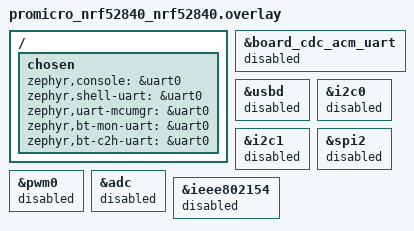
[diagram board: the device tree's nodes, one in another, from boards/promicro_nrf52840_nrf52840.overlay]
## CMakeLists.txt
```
cmake_minimum_required(VERSION 3.20)
find_package(Zephyr REQUIRED HINTS $ENV{ZEPHYR_BASE})
project(helix_nrf52840_mocap_bridge)

get_filename_component(HELIX_ROOT "${CMAKE_CURRENT_LIST_DIR}/../.." ABSOLUTE)

target_sources(app PRIVATE
  src/usbd_init.c
  src/main.cpp
  src/ota_hub_relay.cpp
  ${HELIX_ROOT}/firmware/common/ota/BleOtaService.cpp
)

# OTA flash backend and manager only needed for Tags (node role with MCUboot)
if(CONFIG_HELIX_MOCAP_BRIDGE_ROLE_NODE)
  target_sources(app PRIVATE
    src/ZephyrOtaFlashBackend.cpp
    ${HELIX_ROOT}/firmware/common/ota/OtaManager.cpp
  )
endif()

target_include_directories(app PRIVATE
  src
  ${HELIX_ROOT}/firmware/common/ota
)
```

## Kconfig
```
mainmenu "Helix nRF52840 Mocap Bridge"

source "Kconfig.zephyr"

menu "Helix Mocap Bridge"

choice HELIX_MOCAP_BRIDGE_ROLE
	prompt "Bridge role"
	default HELIX_MOCAP_BRIDGE_ROLE_CENTRAL

config HELIX_MOCAP_BRIDGE_ROLE_CENTRAL
	bool "Central / PRX"

config HELIX_MOCAP_BRIDGE_ROLE_NODE
	bool "Synthetic node / PTX"

endchoice

config HELIX_MOCAP_NODE_ID
	int "Node ID"
	range 1 255
	default 1

config HELIX_MOCAP_CENTRAL_ID
	int "Central ID"
	range 0 255
	default 0

config HELIX_MOCAP_PIPE
	int "ESB pipe"
	range 0 7
	default 0

config HELIX_MOCAP_RF_CHANNEL
	int "ESB RF channel"
	range 0 100
	default 40

config HELIX_MOCAP_SEND_PERIOD_MS
	int "Node send period in milliseconds"
	range 5 5000
	default 20

config HELIX_MOCAP_SESSION_TAG
	int "Session tag"
	range 0 255
	default 77

config HELIX_MOCAP_MAX_TRACKED_NODES
	int "Maximum tracked nodes at the central"
	range 1 16
	default 10

config HELIX_MOCAP_USB_WAIT_FOR_DTR_MS
	int "How long the central waits for host DTR before continuing"
	range 0 30000
	default 5000

config HELIX_MOCAP_USB_VID
	hex "USB vendor ID"
	range 0x0001 0xFFFF
	default 0x1915

config HELIX_MOCAP_USB_PID
	hex "USB product ID"
	range 0x0001 0xFFFF
	default 0x1040 if HELIX_MOCAP_BRIDGE_ROLE_CENTRAL
	default 0x1041 if HELIX_MOCAP_BRIDGE_ROLE_NODE

config HELIX_MOCAP_NODE_LED_DEBUG
	bool "Encode node RF state in LED cadence"
	default y if HELIX_MOCAP_BRIDGE_ROLE_NODE
	help
	  When enabled on node builds, the LED cadence indicates node state:
	  fast blink means the node is alive but has not yet confirmed TX success,
	  medium blink means TX is succeeding without sync anchors, and slow blink
	  means sync anchors are being received from the central.

config HELIX_OTA_HUB_RELAY
	bool "Enable OTA relay from Hub to Tags over BLE"
	default y if HELIX_MOCAP_BRIDGE_ROLE_CENTRAL && BT
	help
	  When enabled, the Hub can relay OTA firmware updates from the PC
	  to Tags over BLE. The PC sends UartOtaProtocol frames over USB CDC,
	  the Hub forwards them to a Tag's BLE GATT OTA service.

config HELIX_OTA_BOOT_WINDOW_MS
	int "BLE OTA boot window in milliseconds (0 to skip)"
	range 0 300000
	default 30000 if HELIX_MOCAP_BRIDGE_ROLE_NODE
	default 0
	help
	  Duration of the BLE OTA advertising window at boot. If a BLE
	  connection is made during this window, OTA proceeds. If not,
	  the device transitions to ESB mocap mode. Set to 0 to skip
	  the BLE window entirely and boot straight into ESB.

config HELIX_OTA_TARGET_ID
	hex "OTA target identity"
	default 0x52840071

config HELIX_BOOTLOADER_VERSION_MAJOR
	int "Bootloader (MCUboot) major version — manually bumped"
	default 1
	help
	  MCUboot does not publish its own version to the app, so we track
	  it manually here. Bump whenever MCUboot itself is rebuilt.

config HELIX_BOOTLOADER_VERSION_MINOR
	int "Bootloader (MCUboot) minor version"
	default 0

config HELIX_BOOTLOADER_VERSION_REVISION
	int "Bootloader (MCUboot) revision"
	default 0

config HELIX_OTA_REBOOT_DELAY_MS
	int "Reboot delay after OTA commit (ms)"
	default 300

# Stage 4 TDMA (Path X1) Kconfig was removed in v22 after the FIFO=1
# Hub config change (docs/RF_FIFO1_DISCOVERY.md) superseded Stage 4's
# value proposition. See git tag stage4-tdma-path-x1-reference for
# the implementation, docs/archive/rf/RF_STAGE4_EXPLORATORY.md for
# the design rationale, and docs/reviews/*stage4_fate* for the
# delete decision.

endmenu
```

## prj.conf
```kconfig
CONFIG_GPIO=y
CONFIG_SERIAL=y
CONFIG_CONSOLE=y
CONFIG_UART_CONSOLE=y
CONFIG_PRINTK=y
CONFIG_UART_LINE_CTRL=y

CONFIG_LOG=y
CONFIG_LOG_MODE_IMMEDIATE=y
CONFIG_LOG_DEFAULT_LEVEL=3
CONFIG_LOG_BACKEND_UART=y
CONFIG_LOG_PRINTK=y

CONFIG_ESB=y
CONFIG_MAIN_STACK_SIZE=3072
```

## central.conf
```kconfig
CONFIG_HELIX_MOCAP_BRIDGE_ROLE_CENTRAL=y
CONFIG_HELIX_MOCAP_BRIDGE_ROLE_NODE=n

CONFIG_USB_DEVICE_STACK_NEXT=y
CONFIG_CDC_ACM_SERIAL_INITIALIZE_AT_BOOT=n
CONFIG_USBD_CDC_ACM_CLASS=y
CONFIG_USBD_LOG_LEVEL_ERR=y
CONFIG_UDC_DRIVER_LOG_LEVEL_ERR=y
CONFIG_USBD_CDC_ACM_LOG_LEVEL_ERR=y

# C++ support for OTA relay modules
CONFIG_CPP=y
CONFIG_NEWLIB_LIBC=y
CONFIG_STD_CPP17=y

# BLE central for OTA relay to Tags
CONFIG_BT=y
CONFIG_BT_CENTRAL=y
CONFIG_BT_GATT_CLIENT=y
# Auto-exchange ATT MTU on connect. Without this, MTU stays at the spec
# default of 23 bytes and bt_gatt_write() for payloads > 20 B (e.g. our
# 132 B OTA data chunks) falls back to Prepare/Execute Write, which the
# Tag's OTA data characteristic rejects with BT_ATT_ERR_NOT_SUPPORTED (0x06).
CONFIG_BT_GATT_AUTO_UPDATE_MTU=y
CONFIG_BT_DEVICE_NAME="HHub"
CONFIG_BT_DEVICE_NAME_DYNAMIC=y
CONFIG_BT_DEVICE_NAME_MAX=16
CONFIG_BT_MAX_CONN=1
CONFIG_BT_L2CAP_TX_MTU=247
CONFIG_BT_BUF_ACL_TX_SIZE=251
CONFIG_BT_BUF_ACL_RX_SIZE=251
CONFIG_BT_CTLR_DATA_LENGTH_MAX=251
CONFIG_BT_CTLR_PHY_2M=y

# Suppress BLE log spam during relay (prevents TX buffer overflow)
CONFIG_BT_LOG_LEVEL_ERR=y
CONFIG_BT_HCI_CORE_LOG_LEVEL_ERR=y

# ESB+BLE coexistence: same pattern as Tags
CONFIG_ESB_DYNAMIC_INTERRUPTS=y

# Force FIFO depth 1 (experiment 2026-04-23): the default ESB_TX_FIFO_SIZE=8
# lets Hub queue up to 8 anchors deep. Combined with asymmetric FIFO drain
# on slow-path ACK transmission, that drives a ~10ms bias in the Stage 3
# midpoint estimator (see docs/RF_V20_FINDINGS.md). Depth 1 forces only ONE
# in-flight anchor at a time; if Hub misses the TIFS window, the anchor is
# simply not queued (rather than piling up in FIFO). The Stage 2 rx_node_id
# filter should absorb the resulting "empty ACK" cases on Tags.
CONFIG_ESB_TX_FIFO_SIZE=1
CONFIG_MPSL_DYNAMIC_INTERRUPTS=y
CONFIG_BT_UNINIT_MPSL_ON_DISABLE=y
CONFIG_BT_LL_SOFTDEVICE=y

# USB CDC RX for receiving OTA commands from PC
CONFIG_UART_INTERRUPT_DRIVEN=y

# Stack/heap for BLE + ESB + C++ + USB
CONFIG_HEAP_MEM_POOL_SIZE=8192
CONFIG_MAIN_STACK_SIZE=8192
CONFIG_SYSTEM_WORKQUEUE_STACK_SIZE=4096

CONFIG_REBOOT=y
```

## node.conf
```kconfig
CONFIG_HELIX_MOCAP_BRIDGE_ROLE_NODE=y
CONFIG_HELIX_MOCAP_BRIDGE_ROLE_CENTRAL=n

# Stage 4 TDMA was deleted in v22 after FIFO=1 superseded it. The
# CONFIG_HELIX_STAGE4_* Kconfig entries no longer exist; see
# docs/archive/rf/RF_STAGE4_EXPLORATORY.md for the history.

# C++ support for OTA modules
CONFIG_CPP=y
CONFIG_NEWLIB_LIBC=y
CONFIG_STD_CPP17=y

# Flash + MCUboot for OTA
CONFIG_FLASH=y
CONFIG_FLASH_MAP=y
CONFIG_FLASH_PAGE_LAYOUT=y
CONFIG_STREAM_FLASH=y
CONFIG_BOOTLOADER_MCUBOOT=y
CONFIG_IMG_MANAGER=y
CONFIG_MCUBOOT_IMG_MANAGER=y
CONFIG_MCUBOOT_IMGTOOL_SIGN_VERSION="22.0.0+0"
CONFIG_REBOOT=y

# BLE for OTA boot window
CONFIG_BT=y
CONFIG_BT_PERIPHERAL=y
CONFIG_BT_DEVICE_NAME="HTag"
CONFIG_BT_DEVICE_NAME_DYNAMIC=y
CONFIG_BT_DEVICE_NAME_MAX=16
CONFIG_BT_DEVICE_APPEARANCE=0
CONFIG_BT_MAX_CONN=1
CONFIG_BT_MAX_PAIRED=1
CONFIG_BT_GATT_DYNAMIC_DB=n
CONFIG_BT_L2CAP_TX_MTU=247
CONFIG_BT_BUF_ACL_TX_SIZE=251
CONFIG_BT_BUF_ACL_RX_SIZE=251
CONFIG_BT_CTLR_DATA_LENGTH_MAX=251
CONFIG_BT_CTLR_PHY_2M=y
# Extra ACL RX headroom for OTA data bursts from the Hub
CONFIG_BT_BUF_ACL_RX_COUNT_EXTRA=6

# ESB must use dynamic interrupts so radio can be released for BLE
CONFIG_ESB_DYNAMIC_INTERRUPTS=y

# MPSL dynamic interrupts + BLE uninit: allows bt_disable() to fully
# release TIMER0/RTC0/RADIO so ESB can claim them after the OTA window.
# Without these, bt_disable() leaves MPSL IRQ handlers active and
# esb_init() causes a HardFault trying to install its own handlers.
CONFIG_MPSL_DYNAMIC_INTERRUPTS=y
CONFIG_BT_UNINIT_MPSL_ON_DISABLE=y
CONFIG_BT_LL_SOFTDEVICE=y

# Stack/heap for BLE + ESB + C++
CONFIG_HEAP_MEM_POOL_SIZE=8192
CONFIG_MAIN_STACK_SIZE=8192
CONFIG_SYSTEM_WORKQUEUE_STACK_SIZE=4096

# BLE OTA window must exceed the OTA transfer duration:
# direct BLE ~3 min, Hub relay ~46s. 300s gives plenty of headroom.
CONFIG_HELIX_OTA_BOOT_WINDOW_MS=300000
```

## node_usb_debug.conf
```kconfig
CONFIG_USB_DEVICE_STACK_NEXT=y
CONFIG_CDC_ACM_SERIAL_INITIALIZE_AT_BOOT=n
CONFIG_USBD_CDC_ACM_CLASS=y
CONFIG_USBD_LOG_LEVEL_ERR=y
CONFIG_UDC_DRIVER_LOG_LEVEL_ERR=y
CONFIG_USBD_CDC_ACM_LOG_LEVEL_ERR=y
CONFIG_HELIX_MOCAP_USB_WAIT_FOR_DTR_MS=0
```

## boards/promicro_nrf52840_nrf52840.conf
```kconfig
# ProPico board-specific overrides for the mocap bridge
CONFIG_BOARD_SERIAL_BACKEND_CDC_ACM=n
CONFIG_USB_DEVICE_STACK=n
CONFIG_USB_DEVICE_STACK_NEXT=n
CONFIG_BOARD_HAS_NRF5_BOOTLOADER=n
```

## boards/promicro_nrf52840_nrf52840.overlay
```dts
/*
 * ProPico nRF52840 overlay for the mocap bridge (Tag node role).
 * Redirect console from USB CDC ACM to physical UART and disable
 * unused peripherals.
 */

/ {
	chosen {
		zephyr,console     = &uart0;
		zephyr,shell-uart  = &uart0;
		zephyr,uart-mcumgr = &uart0;
		zephyr,bt-mon-uart = &uart0;
		zephyr,bt-c2h-uart = &uart0;
	};
};

&board_cdc_acm_uart {
	status = "disabled";
};

&usbd {
	status = "disabled";
};

&i2c0 {
	status = "disabled";
};

&i2c1 {
	status = "disabled";
};

&spi2 {
	status = "disabled";
};

&pwm0 {
	status = "disabled";
};

&adc {
	status = "disabled";
};

&ieee802154 {
	status = "disabled";
};
```

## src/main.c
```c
#include <zephyr/device.h>
#include <zephyr/devicetree.h>
#include <zephyr/drivers/clock_control.h>
#include <zephyr/drivers/clock_control/nrf_clock_control.h>
#include <zephyr/drivers/gpio.h>
#include <zephyr/drivers/uart.h>
#include <zephyr/kernel.h>
#include <zephyr/logging/log.h>
#include <zephyr/sys/atomic.h>
#include <zephyr/sys/printk.h>
#include <zephyr/types.h>
#include <string.h>

#include <esb.h>

#include "usbd_init.h"

LOG_MODULE_REGISTER(helix_mocap_bridge, LOG_LEVEL_INF);

enum {
	HELIX_PACKET_SYNC_ANCHOR = 0xA1,
	HELIX_PACKET_MOCAP_FRAME = 0xC1,
};

struct __packed HelixSyncAnchor {
	uint8_t type;
	uint8_t central_id;
	uint8_t anchor_sequence;
	uint8_t session_tag;
	uint32_t central_timestamp_us;
};

struct __packed HelixMocapFrame {
	uint8_t type;
	uint8_t node_id;
	uint8_t sequence;
	uint8_t session_tag;
	uint32_t node_local_timestamp_us;
	uint32_t node_synced_timestamp_us;
	int16_t yaw_cdeg;
	int16_t pitch_cdeg;
	int16_t roll_cdeg;
	int16_t x_mm;
	int16_t y_mm;
	int16_t z_mm;
};

struct HelixMocapStatus {
	uint32_t magic;
	uint32_t role;
	uint32_t heartbeat;
	uint32_t phase;
	uint32_t tx_attempts;
	uint32_t tx_success;
	uint32_t tx_failed;
	uint32_t rx_packets;
	uint32_t anchors_sent;
	uint32_t anchors_received;
	uint32_t usb_lines;
	uint32_t tracked_nodes;
	int32_t estimated_offset_us;
	uint32_t last_node_id;
	uint32_t last_sequence;
	uint32_t last_rx_len;
	uint32_t last_error;
};

struct NodeTrack {
	uint8_t node_id;
	bool active;
	uint32_t packets;
	uint32_t gaps;
	uint8_t last_sequence;
	uint32_t last_node_timestamp_us;
	uint32_t last_synced_timestamp_us;
	uint32_t last_rx_timestamp_us;
};

volatile struct HelixMocapStatus g_helixMocapStatus;

static const struct gpio_dt_spec led = GPIO_DT_SPEC_GET_OR(DT_ALIAS(led0), gpios, {0});
static const struct device *const host_stream = DEVICE_DT_GET(DT_CHOSEN(zephyr_console));
static struct esb_payload rx_payload;
#if defined(CONFIG_HELIX_MOCAP_BRIDGE_ROLE_NODE)
static struct esb_payload tx_payload;
static atomic_t tx_ready = ATOMIC_INIT(1);
static bool have_anchor;
static int32_t estimated_offset_us;
#endif
#if defined(CONFIG_HELIX_MOCAP_BRIDGE_ROLE_CENTRAL)
static struct NodeTrack tracked_nodes[CONFIG_HELIX_MOCAP_MAX_TRACKED_NODES];
static uint8_t next_anchor_sequence;
#endif

static uint32_t now_us(void)
{
	return (uint32_t)(k_uptime_get() * 1000LL);
}

static void status_set_error(int err)
{
	g_helixMocapStatus.last_error = (uint32_t)(err < 0 ? -err : err);
}

static int clocks_start(void)
{
	int err;
	int res;
	struct onoff_manager *clk_mgr;
	struct onoff_client clk_cli;

	clk_mgr = z_nrf_clock_control_get_onoff(CLOCK_CONTROL_NRF_SUBSYS_HF);
	if (clk_mgr == NULL) {
		return -ENXIO;
	}

	sys_notify_init_spinwait(&clk_cli.notify);
	err = onoff_request(clk_mgr, &clk_cli);
	if (err < 0) {
		return err;
	}

	do {
		err = sys_notify_fetch_result(&clk_cli.notify, &res);
		if (!err && res) {
			return res;
		}
	} while (err);

	return 0;
}

static void led_set(bool on)
{
	if (!gpio_is_ready_dt(&led)) {
		return;
	}

	(void)gpio_pin_set_dt(&led, on ? 1 : 0);
}

static void heartbeat_tick(void)
{
	static bool on;

#if defined(CONFIG_HELIX_MOCAP_BRIDGE_ROLE_NODE) && defined(CONFIG_HELIX_MOCAP_NODE_LED_DEBUG)
	uint32_t period_ms = 125U;

	if (have_anchor) {
		period_ms = 500U;
	} else if (g_helixMocapStatus.tx_success > 0U) {
		period_ms = 250U;
	}

	led_set(((now_us() / 1000U) / period_ms) & 1U);
#else
	on = !on;
	led_set(on);
#endif
	g_helixMocapStatus.heartbeat++;
}

static void host_write(const char *line)
{
	if (!device_is_ready(host_stream)) {
		return;
	}

	for (const char *p = line; *p != '\0'; ++p) {
		uart_poll_out(host_stream, (unsigned char)*p);
	}
}

static void report_summary(void)
{
	char line[192];

#if defined(CONFIG_HELIX_MOCAP_BRIDGE_ROLE_CENTRAL)
	snprintk(line,
		 sizeof(line),
		 "SUMMARY role=central rx=%u anchors=%u tracked=%u usb_lines=%u err=%u hb=%u\n",
		 g_helixMocapStatus.rx_packets,
		 g_helixMocapStatus.anchors_sent,
		 g_helixMocapStatus.tracked_nodes,
		 g_helixMocapStatus.usb_lines,
		 g_helixMocapStatus.last_error,
		 g_helixMocapStatus.heartbeat);
#else
	snprintk(line,
		 sizeof(line),
		 "SUMMARY role=node id=%u tx_ok=%u tx_fail=%u anchors=%u offset_us=%d err=%u hb=%u\n",
		 CONFIG_HELIX_MOCAP_NODE_ID,
		 g_helixMocapStatus.tx_success,
		 g_helixMocapStatus.tx_failed,
		 g_helixMocapStatus.anchors_received,
		 g_helixMocapStatus.estimated_offset_us,
		 g_helixMocapStatus.last_error,
		 g_helixMocapStatus.heartbeat);
#endif

	host_write(line);
}

#if defined(CONFIG_USB_DEVICE_STACK) || defined(CONFIG_USB_DEVICE_STACK_NEXT)
static int host_stream_init(void)
{
	if (!device_is_ready(host_stream)) {
		return -ENODEV;
	}

	return helix_usbd_enable(host_stream, CONFIG_HELIX_MOCAP_USB_WAIT_FOR_DTR_MS);
}
#else
static int host_stream_init(void)
{
	return device_is_ready(host_stream) ? 0 : -ENODEV;
}
#endif

#if defined(CONFIG_HELIX_MOCAP_BRIDGE_ROLE_CENTRAL)
static struct NodeTrack *find_or_add_track(uint8_t node_id)
{
	struct NodeTrack *free_slot = NULL;

	for (size_t i = 0; i < ARRAY_SIZE(tracked_nodes); ++i) {
		if (tracked_nodes[i].active && tracked_nodes[i].node_id == node_id) {
			return &tracked_nodes[i];
		}
		if (!tracked_nodes[i].active && free_slot == NULL) {
			free_slot = &tracked_nodes[i];
		}
	}

	if (free_slot == NULL) {
		return NULL;
	}

	free_slot->active = true;
	free_slot->node_id = node_id;
	g_helixMocapStatus.tracked_nodes++;
	return free_slot;
}

static void host_emit_frame(const struct HelixMocapFrame *frame, uint32_t rx_timestamp_us,
			    uint32_t gaps)
{
	char line[224];

	snprintk(line,
		 sizeof(line),
		 "FRAME node=%u seq=%u node_us=%u sync_us=%u rx_us=%u yaw_cd=%d pitch_cd=%d roll_cd=%d x_mm=%d y_mm=%d z_mm=%d gaps=%u\n",
		 frame->node_id,
		 frame->sequence,
		 frame->node_local_timestamp_us,
		 frame->node_synced_timestamp_us,
		 rx_timestamp_us,
		 frame->yaw_cdeg,
		 frame->pitch_cdeg,
		 frame->roll_cdeg,
		 frame->x_mm,
		 frame->y_mm,
		 frame->z_mm,
		 gaps);
	host_write(line);
	g_helixMocapStatus.usb_lines++;
}

static void central_handle_frame(const struct esb_payload *payload)
{
	const struct HelixMocapFrame *frame = (const struct HelixMocapFrame *)payload->data;
	struct NodeTrack *track;
	uint32_t rx_timestamp_us = now_us();
	uint32_t gaps = 0U;

	if (payload->length < sizeof(*frame) ||
	    frame->type != HELIX_PACKET_MOCAP_FRAME ||
	    frame->session_tag != (uint8_t)CONFIG_HELIX_MOCAP_SESSION_TAG) {
		return;
	}

	track = find_or_add_track(frame->node_id);
	if (track == NULL) {
		return;
	}

	if (track->packets > 0U) {
		const uint8_t expected = (uint8_t)(track->last_sequence + 1U);
		if (frame->sequence != expected) {
			gaps = (uint8_t)(frame->sequence - expected);
			track->gaps += gaps;
		}
	}

	track->packets++;
	track->last_sequence = frame->sequence;
	track->last_node_timestamp_us = frame->node_local_timestamp_us;
	track->last_synced_timestamp_us = frame->node_synced_timestamp_us;
	track->last_rx_timestamp_us = rx_timestamp_us;

	g_helixMocapStatus.last_node_id = frame->node_id;
	g_helixMocapStatus.last_sequence = frame->sequence;

	host_emit_frame(frame, rx_timestamp_us, gaps);

	struct HelixSyncAnchor anchor = {
		.type = HELIX_PACKET_SYNC_ANCHOR,
		.central_id = (uint8_t)CONFIG_HELIX_MOCAP_CENTRAL_ID,
		.anchor_sequence = next_anchor_sequence++,
		.session_tag = (uint8_t)CONFIG_HELIX_MOCAP_SESSION_TAG,
		.central_timestamp_us = rx_timestamp_us,
	};
	struct esb_payload ack = {
		.pipe = payload->pipe,
		.length = sizeof(anchor),
	};

	memcpy(ack.data, &anchor, sizeof(anchor));
	if (esb_write_payload(&ack) == 0) {
		g_helixMocapStatus.anchors_sent++;
	}
}
#endif

#if defined(CONFIG_HELIX_MOCAP_BRIDGE_ROLE_NODE)
static int16_t synth_wave(uint8_t sequence, int32_t mul, int32_t span)
{
	int32_t phase = ((int32_t)sequence * mul) % (span * 2);

	if (phase > span) {
		phase = (span * 2) - phase;
	}

	return (int16_t)(phase - (span / 2));
}

static void node_fill_frame(struct HelixMocapFrame *frame)
{
	const uint8_t sequence = (uint8_t)(g_helixMocapStatus.tx_attempts & 0xFF);
	const uint32_t local_us = now_us();
	const uint32_t synced_us = local_us - (uint32_t)estimated_offset_us;

	frame->type = HELIX_PACKET_MOCAP_FRAME;
	frame->node_id = (uint8_t)CONFIG_HELIX_MOCAP_NODE_ID;
	frame->sequence = sequence;
	frame->session_tag = (uint8_t)CONFIG_HELIX_MOCAP_SESSION_TAG;
	frame->node_local_timestamp_us = local_us;
	frame->node_synced_timestamp_us = synced_us;
	frame->yaw_cdeg = synth_wave(sequence, 37, 3600);
	frame->pitch_cdeg = synth_wave(sequence, 23, 1800);
	frame->roll_cdeg = synth_wave(sequence, 17, 1800);
	frame->x_mm = synth_wave(sequence, 11, 1200);
	frame->y_mm = synth_wave(sequence, 13, 1200);
	frame->z_mm = synth_wave(sequence, 19, 1200);
}

static void node_handle_anchor(const struct esb_payload *payload)
{
	const struct HelixSyncAnchor *anchor = (const struct HelixSyncAnchor *)payload->data;
	const uint32_t local_us = now_us();

	if (payload->length < sizeof(*anchor) ||
	    anchor->type != HELIX_PACKET_SYNC_ANCHOR ||
	    anchor->session_tag != (uint8_t)CONFIG_HELIX_MOCAP_SESSION_TAG) {
		return;
	}

	estimated_offset_us = (int32_t)(local_us - anchor->central_timestamp_us);
	g_helixMocapStatus.estimated_offset_us = estimated_offset_us;
	g_helixMocapStatus.anchors_received++;
	have_anchor = true;
}
#endif

static void event_handler(struct esb_evt const *event)
{
	switch (event->evt_id) {
	case ESB_EVENT_TX_SUCCESS:
		g_helixMocapStatus.tx_success++;
#if defined(CONFIG_HELIX_MOCAP_BRIDGE_ROLE_NODE)
		atomic_set(&tx_ready, 1);
#endif
		break;
	case ESB_EVENT_TX_FAILED:
		g_helixMocapStatus.tx_failed++;
		(void)esb_flush_tx();
#if defined(CONFIG_HELIX_MOCAP_BRIDGE_ROLE_NODE)
		atomic_set(&tx_ready, 1);
#endif
		break;
	case ESB_EVENT_RX_RECEIVED:
		while (esb_read_rx_payload(&rx_payload) == 0) {
			g_helixMocapStatus.rx_packets++;
			g_helixMocapStatus.last_rx_len = rx_payload.length;
#if defined(CONFIG_HELIX_MOCAP_BRIDGE_ROLE_CENTRAL)
			central_handle_frame(&rx_payload);
#else
			node_handle_anchor(&rx_payload);
#endif
		}
		break;
	default:
		break;
	}
}

static int esb_initialize(void)
{
	int err;
	uint8_t base_addr_0[4] = {0xD3, 0xC1, 0xB2, 0xA1};
	uint8_t base_addr_1[4] = {0x44, 0x33, 0x22, 0x11};
	uint8_t addr_prefix[8] = {0xE7, 0xC2, 0xC3, 0xC4, 0xC5, 0xC6, 0xC7, 0xC8};
	struct esb_config config = ESB_DEFAULT_CONFIG;

	config.protocol = ESB_PROTOCOL_ESB_DPL;
	config.bitrate = ESB_BITRATE_2MBPS;
	config.event_handler = event_handler;
	config.retransmit_delay = 600;
	config.retransmit_count = 6;
	config.selective_auto_ack = true;
	config.payload_length = 32;
	config.mode =
#if defined(CONFIG_HELIX_MOCAP_BRIDGE_ROLE_CENTRAL)
		ESB_MODE_PRX;
#else
		ESB_MODE_PTX;
#endif

	err = esb_init(&config);
	if (err) {
		return err;
	}

	err = esb_set_base_address_0(base_addr_0);
	if (err) {
		return err;
	}

	err = esb_set_base_address_1(base_addr_1);
	if (err) {
		return err;
	}

	err = esb_set_prefixes(addr_prefix, ARRAY_SIZE(addr_prefix));
	if (err) {
		return err;
	}

	err = esb_set_rf_channel(CONFIG_HELIX_MOCAP_RF_CHANNEL);
	if (err) {
		return err;
	}

	(void)esb_flush_tx();
	(void)esb_flush_rx();
	return 0;
}

#if defined(CONFIG_HELIX_MOCAP_BRIDGE_ROLE_NODE)
static void maybe_send_frame(void)
{
	struct HelixMocapFrame frame;
	int err;

	if (!atomic_cas(&tx_ready, 1, 0)) {
		return;
	}

	node_fill_frame(&frame);
	tx_payload.pipe = CONFIG_HELIX_MOCAP_PIPE;
	tx_payload.noack = 0;
	tx_payload.length = sizeof(frame);
	memcpy(tx_payload.data, &frame, sizeof(frame));

	g_helixMocapStatus.last_sequence = frame.sequence;
	g_helixMocapStatus.last_node_id = frame.node_id;
	g_helixMocapStatus.tx_attempts++;

	err = esb_write_payload(&tx_payload);
	if (err) {
		status_set_error(err);
		atomic_set(&tx_ready, 1);
	}
}
#endif

int main(void)
{
	int err;

	memset((void *)&g_helixMocapStatus, 0, sizeof(g_helixMocapStatus));
	g_helixMocapStatus.magic = 0x484D4244U;
	g_helixMocapStatus.role =
#if defined(CONFIG_HELIX_MOCAP_BRIDGE_ROLE_CENTRAL)
		1U;
#else
		2U;
#endif
	g_helixMocapStatus.phase = 1U;

	if (gpio_is_ready_dt(&led)) {
		(void)gpio_pin_configure_dt(&led, GPIO_OUTPUT_INACTIVE);
	}

	err = clocks_start();
	if (err) {
		status_set_error(err);
	}
	g_helixMocapStatus.phase = 2U;

	err = host_stream_init();
	if (err) {
		status_set_error(err);
	}
	g_helixMocapStatus.phase = 3U;

	err = esb_initialize();
	if (err) {
		status_set_error(err);
	}
	g_helixMocapStatus.phase = 4U;

#if defined(CONFIG_HELIX_MOCAP_BRIDGE_ROLE_CENTRAL)
	err = esb_start_rx();
	if (err) {
		status_set_error(err);
	}
#endif

	host_write("HELIX_MOCAP_BRIDGE_READY\n");

	while (1) {
		heartbeat_tick();
#if defined(CONFIG_HELIX_MOCAP_BRIDGE_ROLE_NODE)
		maybe_send_frame();
#endif
		if ((g_helixMocapStatus.heartbeat % 25U) == 0U) {
			report_summary();
		}
		k_sleep(K_MSEC(CONFIG_HELIX_MOCAP_SEND_PERIOD_MS));
	}

	return 0;
}
```

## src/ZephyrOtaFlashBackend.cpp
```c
#include "ZephyrOtaFlashBackend.hpp"

#include <string.h>
#include <zephyr/autoconf.h>
#include <zephyr/devicetree/fixed-partitions.h>
#include <zephyr/dfu/mcuboot.h>
#include <zephyr/storage/flash_map.h>

#if __has_include(<pm_config.h>)
#include <pm_config.h>
#endif

namespace helix {

bool ZephyrOtaFlashBackend::init() {
    if (slot1_) {
        return true;
    }
    /* Use the partition manager's mcuboot_secondary ID (from pm_static.yml)
     * rather than DTS slot1_partition. The DTS label and PM partition can
     * resolve to DIFFERENT flash addresses; MCUboot & imgtool use the PM
     * definition, so we must too.  On this nRF52840 build:
     *   DTS slot1_partition = 0x82000 (wrong)
     *   PM_MCUBOOT_SECONDARY = 0x85000 (right) */
#if defined(PM_MCUBOOT_SECONDARY_ID)
    return flash_area_open(PM_MCUBOOT_SECONDARY_ID, &slot1_) == 0;
#else
    return flash_area_open(FIXED_PARTITION_ID(slot1_partition), &slot1_) == 0;
#endif
}

uint32_t ZephyrOtaFlashBackend::slotSize() const {
    return slot1_ ? slot1_->fa_size : 0u;
}

bool ZephyrOtaFlashBackend::eraseSlot() {
    if (!slot1_ || flash_area_erase(slot1_, 0, slot1_->fa_size) != 0) {
        return false;
    }
    nextWriteOffset_ = 0u;
    bufferBaseOffset_ = 0u;
    bufferedBytes_ = 0u;
    return true;
}

bool ZephyrOtaFlashBackend::writeChunk(uint32_t offset, const uint8_t* data, size_t len) {
    if (!slot1_ || !data || offset != nextWriteOffset_ || offset + len > slot1_->fa_size) {
        return false;
    }

    size_t consumed = 0u;
    while (consumed < len) {
        if (bufferedBytes_ == 0u) {
            bufferBaseOffset_ = offset + static_cast<uint32_t>(consumed);
        }

        const size_t space = kFlashBatchBytes - bufferedBytes_;
        const size_t copyLen = (len - consumed < space) ? (len - consumed) : space;
        memcpy(buffer_ + bufferedBytes_, data + consumed, copyLen);
        bufferedBytes_ += copyLen;
        consumed += copyLen;

        if (bufferedBytes_ == kFlashBatchBytes && !flushBuffered()) {
            return false;
        }
    }

    nextWriteOffset_ += static_cast<uint32_t>(len);
    return true;
}

bool ZephyrOtaFlashBackend::setPendingUpgrade() {
    if (!flushBuffered() || !slot1_) {
        return false;
    }
    /* Use Zephyr's official API to request the upgrade. BOOT_UPGRADE_PERMANENT
     * (nonzero) so MCUboot doesn't require a confirm after reboot. */
    return boot_request_upgrade(BOOT_UPGRADE_PERMANENT) == 0;
}

bool ZephyrOtaFlashBackend::flushBuffered() {
    if (!slot1_ || bufferedBytes_ == 0u) {
        return true;
    }

    const uint32_t align = flash_area_align(slot1_);
    size_t writeLen = bufferedBytes_;
    if (align > 1u) {
        const size_t remainder = writeLen % align;
        if (remainder != 0u) {
            const size_t paddedLen = writeLen + (align - remainder);
            if (paddedLen > sizeof(buffer_)) {
                return false;
            }
            memset(buffer_ + writeLen, 0xFF, paddedLen - writeLen);
            writeLen = paddedLen;
        }
    }

    if (flash_area_write(slot1_, bufferBaseOffset_, buffer_, writeLen) != 0) {
        return false;
    }

    bufferedBytes_ = 0u;
    return true;
}

} // namespace helix
```

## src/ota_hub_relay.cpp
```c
#include "ota_hub_relay.hpp"

#if defined(CONFIG_HELIX_OTA_HUB_RELAY)

#include <zephyr/drivers/uart.h>
#include <zephyr/kernel.h>
#include <zephyr/sys/printk.h>
#include <string.h>

extern "C" {
#include <zephyr/bluetooth/bluetooth.h>
#include <zephyr/bluetooth/conn.h>
#include <zephyr/bluetooth/gatt.h>
#include <zephyr/bluetooth/uuid.h>
}

#include "UartOtaProtocol.hpp"

/* Declared in main.cpp — requests the Hub to inject an ESB OTA trigger
 * into ACK payloads for the target node. retries=0 means one-shot. */
extern "C" void helix_request_ota_trigger(uint8_t node_id, uint8_t retries);

using helix::UartOtaProtocol;
using helix::UartOtaMutableFrame;
using helix::UartOtaFrameParser;

/* ── USB CDC RX ────────────────────────────────────────────────── */
/* The new USB device stack (CONFIG_USB_DEVICE_STACK_NEXT) only primes
 * the bulk OUT endpoint when uart_irq_rx_enable() is called. Pure
 * uart_poll_in() never triggers endpoint queueing, so the host write
 * hangs indefinitely. We call uart_irq_rx_enable() at init to prime
 * the endpoint, then use uart_poll_in() to read from the internal
 * ring buffer. The endpoint re-primes on each read. */

static const struct device *host_dev;
static UartOtaFrameParser<512> parser;

/* IRQ-driven RX: the CDC ACM callback runs in the system workqueue
 * context and drains data from the CDC ACM internal FIFO into our
 * ring buffer. The main loop reads from our ring buffer. */
#define RX_RING_SIZE 512
static uint8_t rx_ring_buf[RX_RING_SIZE];
static volatile uint16_t rx_head; /* callback writes */
static volatile uint16_t rx_tail; /* main loop reads */

static void uart_rx_callback(const struct device *dev, void *user_data)
{
	ARG_UNUSED(user_data);

	while (uart_irq_update(dev) && uart_irq_is_pending(dev)) {
		if (uart_irq_rx_ready(dev)) {
			uint8_t buf[64];
			int len = uart_fifo_read(dev, buf, sizeof(buf));
			for (int i = 0; i < len; ++i) {
				uint16_t next = (rx_head + 1) % RX_RING_SIZE;
				if (next != rx_tail) {
					rx_ring_buf[rx_head] = buf[i];
					rx_head = next;
				}
			}
		}
	}
}

static bool rx_ring_get(uint8_t *byte)
{
	if (rx_tail == rx_head) {
		return false;
	}
	*byte = rx_ring_buf[rx_tail];
	rx_tail = (rx_tail + 1) % RX_RING_SIZE;
	return true;
}

static void host_write_bytes(const uint8_t *data, size_t len)
{
	if (!device_is_ready(host_dev)) {
		return;
	}
	for (size_t i = 0; i < len; ++i) {
		uart_poll_out(host_dev, data[i]);
	}
}

static void send_response(uint8_t type, const uint8_t *payload, size_t payloadLen)
{
	uint8_t buf[128];
	size_t outLen = 0;
	if (UartOtaProtocol::encode(type, payload, payloadLen, buf, sizeof(buf), outLen)) {
		host_write_bytes(buf, outLen);
	}
}

/* ── BLE GATT client ───────────────────────────────────────────── */

#define BT_UUID_HELIX_OTA_SVC   BT_UUID_128_ENCODE(0x3ef6a001, 0x2d3b, 0x4f2a, 0x89e4, 0x7b59d1c0a001)
#define BT_UUID_HELIX_OTA_CTRL  BT_UUID_128_ENCODE(0x3ef6a002, 0x2d3b, 0x4f2a, 0x89e4, 0x7b59d1c0a001)
#define BT_UUID_HELIX_OTA_DATA  BT_UUID_128_ENCODE(0x3ef6a003, 0x2d3b, 0x4f2a, 0x89e4, 0x7b59d1c0a001)
#define BT_UUID_HELIX_OTA_STAT  BT_UUID_128_ENCODE(0x3ef6a004, 0x2d3b, 0x4f2a, 0x89e4, 0x7b59d1c0a001)

static struct bt_uuid_128 ota_svc_uuid  = BT_UUID_INIT_128(BT_UUID_HELIX_OTA_SVC);
static struct bt_uuid_128 ota_ctrl_uuid = BT_UUID_INIT_128(BT_UUID_HELIX_OTA_CTRL);
static struct bt_uuid_128 ota_data_uuid = BT_UUID_INIT_128(BT_UUID_HELIX_OTA_DATA);
static struct bt_uuid_128 ota_stat_uuid = BT_UUID_INIT_128(BT_UUID_HELIX_OTA_STAT);

static struct bt_conn *relay_conn;
static uint16_t gatt_ctrl_handle;
static uint16_t gatt_data_handle;
static uint16_t gatt_stat_handle;

enum class RelayState : uint8_t {
	IDLE,
	BLE_INIT,
	SCANNING,
	CONNECTING,
	DISCOVERING,
	READY,
	DONE,
	ERR,
};

static volatile RelayState relay_state = RelayState::IDLE;
static char target_name[16];
static volatile bool gatt_write_done;
static volatile int gatt_write_err;
static volatile bool gatt_read_done;
static uint8_t gatt_read_buf[32];
static volatile size_t gatt_read_len;

/* ── Scan callback ─────────────────────────────────────────────── */

static void scan_result_cb(const bt_addr_le_t *addr, int8_t rssi,
                           uint8_t adv_type, struct net_buf_simple *buf)
{
	ARG_UNUSED(rssi);
	ARG_UNUSED(adv_type);

	/* Parse all AD structures in one pass, capturing name and
	 * manufacturer data. */
	char found_name[16] = {};
	uint8_t mfg_buf[24] = {};
	uint8_t mfg_len = 0;

	while (buf->len > 1) {
		uint8_t len = net_buf_simple_pull_u8(buf);
		if (len == 0 || len > buf->len) {
			break;
		}
		uint8_t type = net_buf_simple_pull_u8(buf);
		len--;
		if ((type == BT_DATA_NAME_COMPLETE || type == BT_DATA_NAME_SHORTENED) &&
		    len > 0 && len < sizeof(found_name)) {
			memcpy(found_name, buf->data, len);
			found_name[len] = '\0';
		} else if (type == BT_DATA_MANUFACTURER_DATA &&
		           len > 0 && len <= sizeof(mfg_buf)) {
			memcpy(mfg_buf, buf->data, len);
			mfg_len = len;
		}
		net_buf_simple_pull(buf, len);
	}

	if (found_name[0] == '\0' ||
	    strncmp(found_name, target_name, strlen(target_name)) != 0) {
		return;
	}

	printk("relay: found %s (mfg %u bytes:", found_name, mfg_len);
	for (uint8_t i = 0; i < mfg_len && i < 16; i++) {
		printk(" %02x", mfg_buf[i]);
	}
	printk(")\n");

	bt_le_scan_stop();
	static const struct bt_conn_le_create_param create_param = {
		.options = BT_CONN_LE_OPT_NONE,
		.interval = BT_GAP_SCAN_FAST_INTERVAL,
		.window = BT_GAP_SCAN_FAST_WINDOW,
		.interval_coded = 0,
		.window_coded = 0,
		.timeout = 0,
	};
	static const struct bt_le_conn_param conn_param = {
		.interval_min = BT_GAP_INIT_CONN_INT_MIN,
		.interval_max = BT_GAP_INIT_CONN_INT_MAX,
		.latency = 0,
		.timeout = 3200, /* 32s — Tag flash erase takes ~10s */
	};
	int err = bt_conn_le_create(addr, &create_param, &conn_param, &relay_conn);
	if (err) {
		printk("relay: connect failed %d\n", err);
		relay_state = RelayState::ERR;
	} else {
		relay_state = RelayState::CONNECTING;
	}
}

/* ── Connection callbacks ──────────────────────────────────────── */

static struct bt_gatt_discover_params disc_params;

/* Phase 2: discover characteristics within the service handle range */
static uint8_t discover_chrc_cb(struct bt_conn *conn,
                                const struct bt_gatt_attr *attr,
                                struct bt_gatt_discover_params *params)
{
	if (!attr) {
		printk("relay: discovery done ctrl=%u data=%u stat=%u\n",
		       gatt_ctrl_handle, gatt_data_handle, gatt_stat_handle);
		if (gatt_ctrl_handle && gatt_data_handle && gatt_stat_handle) {
			relay_state = RelayState::READY;
		} else {
			relay_state = RelayState::ERR;
		}
		return BT_GATT_ITER_STOP;
	}

	if (bt_uuid_cmp(attr->uuid, BT_UUID_GATT_CHRC) == 0) {
		const auto *chrc = static_cast<const struct bt_gatt_chrc *>(attr->user_data);
		if (bt_uuid_cmp(chrc->uuid, &ota_ctrl_uuid.uuid) == 0) {
			gatt_ctrl_handle = chrc->value_handle;
		} else if (bt_uuid_cmp(chrc->uuid, &ota_data_uuid.uuid) == 0) {
			gatt_data_handle = chrc->value_handle;
		} else if (bt_uuid_cmp(chrc->uuid, &ota_stat_uuid.uuid) == 0) {
			gatt_stat_handle = chrc->value_handle;
		}
	}
	return BT_GATT_ITER_CONTINUE;
}

/* Phase 1: discover the OTA primary service to get handle range */
static uint8_t discover_svc_cb(struct bt_conn *conn,
                               const struct bt_gatt_attr *attr,
                               struct bt_gatt_discover_params *params)
{
	if (!attr) {
		printk("relay: OTA service not found\n");
		relay_state = RelayState::ERR;
		return BT_GATT_ITER_STOP;
	}

	const auto *svc = static_cast<const struct bt_gatt_service_val *>(attr->user_data);
	printk("relay: OTA svc %u-%u\n", attr->handle, svc->end_handle);

	/* Phase 2: discover characteristics within this service */
	disc_params.uuid = nullptr;
	disc_params.func = discover_chrc_cb;
	disc_params.start_handle = attr->handle + 1;
	disc_params.end_handle = svc->end_handle;
	disc_params.type = BT_GATT_DISCOVER_CHARACTERISTIC;
	bt_gatt_discover(conn, &disc_params);

	return BT_GATT_ITER_STOP;
}

static void relay_connected(struct bt_conn *conn, uint8_t err)
{
	if (err) {
		printk("relay: connection failed %d\n", err);
		relay_state = RelayState::ERR;
		return;
	}
	printk("relay: connected\n");
	relay_state = RelayState::DISCOVERING;

	/* Request longer supervision timeout for flash erase (~10s) */
	{
		static const struct bt_le_conn_param update_param = {
			.interval_min = 6,   /* 7.5ms */
			.interval_max = 24,  /* 30ms */
			.latency = 0,
			.timeout = 3200,     /* 32s */
		};
		bt_conn_le_param_update(conn, &update_param);
	}

	gatt_ctrl_handle = 0;
	gatt_data_handle = 0;
	gatt_stat_handle = 0;

	/* Phase 1: find the OTA primary service */
	disc_params.uuid = &ota_svc_uuid.uuid;
	disc_params.func = discover_svc_cb;
	disc_params.start_handle = BT_ATT_FIRST_ATTRIBUTE_HANDLE;
	disc_params.end_handle = BT_ATT_LAST_ATTRIBUTE_HANDLE;
	disc_params.type = BT_GATT_DISCOVER_PRIMARY;

	bt_gatt_discover(conn, &disc_params);
}

static void relay_disconnected(struct bt_conn *conn, uint8_t reason)
{
	printk("relay: disconnected reason=%u\n", reason);
	if (relay_conn) {
		bt_conn_unref(relay_conn);
		relay_conn = nullptr;
	}
	if (relay_state == RelayState::READY || relay_state == RelayState::DISCOVERING ||
	    relay_state == RelayState::CONNECTING) {
		relay_state = RelayState::ERR;
	}
}

BT_CONN_CB_DEFINE(relay_conn_cbs) = {
	.connected = relay_connected,
	.disconnected = relay_disconnected,
};

/* ── GATT write callback ──────────────────────────────────────── */

static void gatt_write_cb(struct bt_conn *conn, uint8_t err,
                          struct bt_gatt_write_params *params)
{
	gatt_write_err = err;
	gatt_write_done = true;
}

static struct bt_gatt_write_params write_params;

/* ── GATT read callback ───────────────────────────────────────── */

static uint8_t gatt_read_cb(struct bt_conn *conn, uint8_t err,
                            struct bt_gatt_read_params *params,
                            const void *data, uint16_t length)
{
	if (data && length <= sizeof(gatt_read_buf)) {
		memcpy(gatt_read_buf, data, length);
		gatt_read_len = length;
	}
	gatt_read_done = true;
	return BT_GATT_ITER_STOP;
}

static struct bt_gatt_read_params read_params;

/* ── Relay frame handler ──────────────────────────────────────── */

static void handle_relay_frame(const UartOtaMutableFrame &frame)
{
	using FT = UartOtaProtocol::FrameType;
	auto ft = static_cast<FT>(frame.type);

	if (ft == FT::EsbTrigReq) {
		/* Request Hub to inject an ESB OTA trigger for a node.
		 * Payload: [node_id, retries].  ESB is still running at this point. */
		if (frame.payloadLen >= 2) {
			helix_request_ota_trigger(frame.payload[0], frame.payload[1]);
			printk("relay: esb trigger node=%u retries=%u\n",
			       frame.payload[0], frame.payload[1]);
			uint8_t rsp = 0x00;
			send_response(static_cast<uint8_t>(FT::EsbTrigRsp), &rsp, 1);
		} else {
			uint8_t rsp = 0xFF;
			send_response(static_cast<uint8_t>(FT::EsbTrigRsp), &rsp, 1);
		}
		return;
	}

	if (ft == FT::InfoReq) {
		/* Start OTA session: payload is target name (null-terminated string).
		 * Don't send InfoRsp yet — ESB is still running and binary response
		 * bytes would be interleaved with ASCII FRAME data. The response is
		 * deferred until after ESB is stopped (in the BLE_INIT handler). */
		if (relay_state != RelayState::IDLE && relay_state != RelayState::ERR) {
			uint8_t rsp = 0xFF;
			send_response(static_cast<uint8_t>(FT::InfoRsp), &rsp, 1);
			return;
		}

		size_t nameLen = frame.payloadLen < sizeof(target_name) - 1
		                 ? frame.payloadLen : sizeof(target_name) - 1;
		memcpy(target_name, frame.payload, nameLen);
		target_name[nameLen] = '\0';

		printk("relay: OTA target=%s\n", target_name);
		relay_state = RelayState::BLE_INIT;
		return;
	}

	if (relay_state != RelayState::READY) {
		/* Not connected to Tag — reject */
		uint8_t rsp = 0xFF;
		uint8_t rspType = frame.type | 0x01u; /* make it a response type */
		send_response(rspType, &rsp, 1);
		return;
	}

	if (ft == FT::CtrlWrite) {
		/* Forward CTRL write to Tag. Copy payload to a stable buffer
		 * since bt_gatt_write is async and the parser buffer may be
		 * reused during the k_sleep wait. */
		gatt_write_done = false;
		static uint8_t ctrl_buf[64];
		size_t copyLen = frame.payloadLen < sizeof(ctrl_buf)
		                 ? frame.payloadLen : sizeof(ctrl_buf);
		memcpy(ctrl_buf, frame.payload, copyLen);
		write_params.handle = gatt_ctrl_handle;
		write_params.offset = 0;
		write_params.data = ctrl_buf;
		write_params.length = copyLen;
		write_params.func = gatt_write_cb;
		int err = bt_gatt_write(relay_conn, &write_params);
		if (err) {
			uint8_t rsp = 0xFE;
			send_response(static_cast<uint8_t>(FT::CtrlRsp), &rsp, 1);
			return;
		}
		/* Wait for callback — BEGIN triggers flash erase (~10s) */
		for (int i = 0; i < 600 && !gatt_write_done; ++i) {
			k_sleep(K_MSEC(100));
		}
		uint8_t rsp = gatt_write_done ? static_cast<uint8_t>(gatt_write_err) : 0xFD;
		send_response(static_cast<uint8_t>(FT::CtrlRsp), &rsp, 1);

	} else if (ft == FT::DataWrite) {
		/* Use write-WITH-response so Hub waits for Tag's ATT Write Response
		 * per chunk. This gives true flow control — the Tag has processed
		 * the chunk (handleDataWrite returned) before we send the next.
		 * Write-without-response (even with the _cb variant) only waits
		 * for local TX queue, not remote-side processing, so we were
		 * overrunning the Tag's ACL RX buffer + flash-write throughput. */
		static uint8_t dw_buf[256];
		size_t dw_len = frame.payloadLen < sizeof(dw_buf)
		                 ? frame.payloadLen : sizeof(dw_buf);
		memcpy(dw_buf, frame.payload, dw_len);
		gatt_write_done = false;
		write_params.handle = gatt_data_handle;
		write_params.offset = 0;
		write_params.data = dw_buf;
		write_params.length = dw_len;
		write_params.func = gatt_write_cb;
		int err = -ENOMEM;
		for (int retries = 0; err == -ENOMEM && retries < 50; retries++) {
			err = bt_gatt_write(relay_conn, &write_params);
			if (err == -ENOMEM) {
				k_sleep(K_MSEC(5));
			}
		}
		uint8_t dw_rsp;
		if (err == 0) {
			/* Wait up to 2s for Tag's ATT Write Response */
			for (int i = 0; i < 200 && !gatt_write_done; ++i) {
				k_sleep(K_MSEC(10));
			}
			dw_rsp = gatt_write_done ? static_cast<uint8_t>(gatt_write_err) : 0xFD;
		} else {
			dw_rsp = 0xFE;
		}
		/* Send DataRsp so uploader waits for per-chunk ACK — this is the
		 * back-pressure mechanism that prevents the Hub's USB CDC RX ring
		 * buffer from overrunning (uploader sends chunks far faster than
		 * the Hub can relay them over BLE). */
		send_response(static_cast<uint8_t>(FT::DataRsp), &dw_rsp, 1);

	} else if (ft == FT::StatusReq) {
		/* Read Tag's OTA status */
		gatt_read_done = false;
		gatt_read_len = 0;
		read_params.func = gatt_read_cb;
		read_params.handle_count = 1;
		read_params.single.handle = gatt_stat_handle;
		read_params.single.offset = 0;
		int err = bt_gatt_read(relay_conn, &read_params);
		if (err) {
			uint8_t rsp = 0xFE;
			send_response(static_cast<uint8_t>(FT::StatusRsp), &rsp, 1);
			return;
		}
		for (int i = 0; i < 100 && !gatt_read_done; ++i) {
			k_sleep(K_MSEC(100));
		}
		if (gatt_read_done && gatt_read_len > 0) {
			send_response(static_cast<uint8_t>(FT::StatusRsp),
			              gatt_read_buf, gatt_read_len);
		} else {
			uint8_t rsp = 0xFD;
			send_response(static_cast<uint8_t>(FT::StatusRsp), &rsp, 1);
		}
	}
}

/* ── Public API ────────────────────────────────────────────────── */

int ota_hub_relay_init(const struct device *dev)
{
	host_dev = dev;

	/* Set up IRQ-driven RX. The CDC ACM driver in the new USB stack
	 * only primes the bulk OUT endpoint when uart_irq_rx_enable() is
	 * called. The callback drains the CDC ACM FIFO into our ring buffer
	 * using the proper uart_fifo_read API. */
	uart_irq_callback_user_data_set(dev, uart_rx_callback, nullptr);
	uart_irq_rx_enable(dev);
	printk("relay: init OK (irq rx)\n");
	return 0;
}

static uint32_t rx_byte_count;
static uint32_t poll_count;

bool ota_hub_relay_poll(void)
{
	poll_count++;

	/* Drain IRQ ring buffer and feed into frame parser */
	uint8_t byte;
	while (rx_ring_get(&byte)) {
		rx_byte_count++;
		UartOtaMutableFrame frame{};
		if (parser.push(byte, frame)) {
			handle_relay_frame(frame);
		}
	}

	/* Handle BLE init / scan state transitions.
	 * When BLE_INIT is first set (by handle_relay_frame), return
	 * immediately so the main loop can disable ESB before we call
	 * bt_enable(). The radio is shared — ESB must be off first. */
	if (relay_state == RelayState::BLE_INIT) {
		static bool esb_stop_requested;
		if (!esb_stop_requested) {
			esb_stop_requested = true;
			return true; /* signal main loop to stop ESB */
		}
		esb_stop_requested = false;

		/* Let LF clock / MPSL calibrate before bt_enable(). MUST run
		 * BEFORE we ACK the uploader's InfoReq — otherwise the uploader
		 * proceeds with its fixed 3 s post-InfoRsp sleep and sends
		 * StatusReq while we're still in this delay, Hub rejects it
		 * (relay_state != READY), and the uploader bails with
		 * "StatusReq failed". The uploader's InfoRsp timeout is 15 s,
		 * which easily covers this delay. */
		k_sleep(K_MSEC(4000));

		/* Send deferred InfoRsp now that ESB is stopped, CDC TX is clean,
		 * and the LF clock has settled. */
		{
			using FT = UartOtaProtocol::FrameType;
			uint8_t rsp = 0x00;
			send_response(static_cast<uint8_t>(FT::InfoRsp), &rsp, 1);
		}

		int err = bt_enable(nullptr);
		if (err && err != -EALREADY) {
			relay_state = RelayState::ERR;
		} else {
			static const struct bt_le_scan_param scan_param = {
				.type = BT_LE_SCAN_TYPE_PASSIVE,
				.options = BT_LE_SCAN_OPT_NONE,
				.interval = BT_GAP_SCAN_FAST_INTERVAL,
				.window = BT_GAP_SCAN_FAST_WINDOW,
			};
			err = bt_le_scan_start(&scan_param, scan_result_cb);
			if (err) {
				printk("relay: scan start failed %d\n", err);
				relay_state = RelayState::ERR;
			} else {
				relay_state = RelayState::SCANNING;
			}
		}
	}

	return relay_state != RelayState::IDLE;
}

bool ota_hub_relay_needs_esb_stop(void)
{
	/* ESB must be off whenever BLE is needed */
	return relay_state == RelayState::BLE_INIT ||
	       relay_state == RelayState::SCANNING ||
	       relay_state == RelayState::CONNECTING ||
	       relay_state == RelayState::DISCOVERING ||
	       relay_state == RelayState::READY;
}

bool ota_hub_relay_esb_can_restart(void)
{
	if (relay_state == RelayState::DONE || relay_state == RelayState::ERR) {
		if (relay_conn) {
			bt_conn_disconnect(relay_conn, BT_HCI_ERR_REMOTE_USER_TERM_CONN);
			k_sleep(K_MSEC(200));
			if (relay_conn) {
				bt_conn_unref(relay_conn);
				relay_conn = nullptr;
			}
		}
		bt_le_scan_stop();
		bt_disable();
		relay_state = RelayState::IDLE;
		return true;
	}
	return false;
}

uint32_t ota_hub_relay_rx_count(void) { return rx_byte_count; }
uint32_t ota_hub_relay_poll_count(void) { return poll_count; }

#else /* !CONFIG_HELIX_OTA_HUB_RELAY */

int ota_hub_relay_init(const struct device *) { return 0; }
bool ota_hub_relay_poll(void) { return false; }
bool ota_hub_relay_needs_esb_stop(void) { return false; }
bool ota_hub_relay_esb_can_restart(void) { return false; }
uint32_t ota_hub_relay_rx_count(void) { return 0; }
uint32_t ota_hub_relay_poll_count(void) { return 0; }

#endif /* CONFIG_HELIX_OTA_HUB_RELAY */
```

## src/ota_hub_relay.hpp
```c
#pragma once

/* Hub OTA relay: receives UartOtaProtocol frames from PC over USB CDC,
 * forwards them to a Tag's BLE GATT OTA service, returns responses.
 *
 * Call ota_hub_relay_init() after host_stream_init().
 * Call ota_hub_relay_poll() in the main loop to process USB RX.
 * When an OTA session starts, ESB must be stopped and BLE enabled.
 * When the session ends, BLE is disabled and ESB is restarted. */

#include <stdbool.h>
#include <stdint.h>

#ifdef __cplusplus
extern "C" {
#endif

/* Initialize the USB CDC RX ring buffer and frame parser. */
int ota_hub_relay_init(const struct device *host_dev);

/* Poll for USB RX data and process OTA relay frames.
 * Returns true if an OTA session is currently active (ESB should be stopped).
 * Call from the main loop. */
bool ota_hub_relay_poll(void);

/* Check if we need to stop ESB for an OTA session. */
bool ota_hub_relay_needs_esb_stop(void);

/* Check if the OTA session ended and ESB can restart. */
bool ota_hub_relay_esb_can_restart(void);

/* Debug: get total RX byte count and poll count. */
uint32_t ota_hub_relay_rx_count(void);
uint32_t ota_hub_relay_poll_count(void);

#ifdef __cplusplus
}
#endif
```

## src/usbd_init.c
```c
#include "usbd_init.h"

#if defined(CONFIG_USB_DEVICE_STACK_NEXT)

#include <zephyr/drivers/uart.h>
#include <zephyr/kernel.h>
#include <zephyr/usb/usbd.h>

USBD_DEVICE_DEFINE(helix_usbd,
		   DEVICE_DT_GET(DT_NODELABEL(zephyr_udc0)),
		   CONFIG_HELIX_MOCAP_USB_VID, CONFIG_HELIX_MOCAP_USB_PID);
USBD_DESC_LANG_DEFINE(helix_lang);
USBD_DESC_MANUFACTURER_DEFINE(helix_mfr, "HelixDrift");
#if defined(CONFIG_HELIX_MOCAP_BRIDGE_ROLE_CENTRAL)
USBD_DESC_PRODUCT_DEFINE(helix_product, "Helix Mocap Central");
#else
USBD_DESC_PRODUCT_DEFINE(helix_product, "Helix Mocap Node");
#endif
USBD_DESC_CONFIG_DEFINE(helix_fs_cfg_desc, "FS Configuration");

static const uint8_t helix_attributes = USB_SCD_SELF_POWERED;

USBD_CONFIGURATION_DEFINE(helix_fs_config, helix_attributes, 125, &helix_fs_cfg_desc);

static bool helix_usbd_ready;

static void helix_fix_code_triple(struct usbd_context *ctx)
{
	usbd_device_set_code_triple(ctx, USBD_SPEED_FS, USB_BCC_MISCELLANEOUS, 0x02, 0x01);
}

static void helix_usbd_msg_cb(struct usbd_context *const ctx, const struct usbd_msg *msg)
{
	if (usbd_can_detect_vbus(ctx)) {
		if (msg->type == USBD_MSG_VBUS_READY) {
			(void)usbd_enable(ctx);
		} else if (msg->type == USBD_MSG_VBUS_REMOVED) {
			(void)usbd_disable(ctx);
		}
	}
}

static int helix_usbd_init_once(void)
{
	int err;

	if (helix_usbd_ready) {
		return 0;
	}

	err = usbd_add_descriptor(&helix_usbd, &helix_lang);
	if (err) {
		return err;
	}
	err = usbd_add_descriptor(&helix_usbd, &helix_mfr);
	if (err) {
		return err;
	}
	err = usbd_add_descriptor(&helix_usbd, &helix_product);
	if (err) {
		return err;
	}
	err = usbd_add_configuration(&helix_usbd, USBD_SPEED_FS, &helix_fs_config);
	if (err) {
		return err;
	}
	err = usbd_register_all_classes(&helix_usbd, USBD_SPEED_FS, 1, NULL);
	if (err) {
		return err;
	}
	helix_fix_code_triple(&helix_usbd);
	usbd_self_powered(&helix_usbd, true);
	err = usbd_msg_register_cb(&helix_usbd, helix_usbd_msg_cb);
	if (err) {
		return err;
	}
	err = usbd_init(&helix_usbd);
	if (err) {
		return err;
	}

	helix_usbd_ready = true;
	return 0;
}

int helix_usbd_enable(const struct device *console_dev, int wait_for_dtr_ms)
{
	int err;

	err = helix_usbd_init_once();
	if (err) {
		return err;
	}

	if (!usbd_can_detect_vbus(&helix_usbd)) {
		err = usbd_enable(&helix_usbd);
		if (err) {
			return err;
		}
	}

#if DT_NODE_HAS_COMPAT(DT_CHOSEN(zephyr_console), zephyr_cdc_acm_uart)
	if (wait_for_dtr_ms > 0) {
		int64_t deadline = k_uptime_get() + wait_for_dtr_ms;

		while (k_uptime_get() < deadline) {
			uint32_t dtr = 0U;

			(void)uart_line_ctrl_get(console_dev, UART_LINE_CTRL_DTR, &dtr);
			if (dtr != 0U) {
				break;
			}
			k_sleep(K_MSEC(50));
		}
	}
#else
	ARG_UNUSED(console_dev);
	ARG_UNUSED(wait_for_dtr_ms);
#endif

	return 0;
}

#else

int helix_usbd_enable(const struct device *console_dev, int wait_for_dtr_ms)
{
	ARG_UNUSED(console_dev);
	ARG_UNUSED(wait_for_dtr_ms);
	return 0;
}

#endif
```

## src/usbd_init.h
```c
#pragma once

#include <zephyr/device.h>

#ifdef __cplusplus
extern "C" {
#endif

int helix_usbd_enable(const struct device *console_dev, int wait_for_dtr_ms);

#ifdef __cplusplus
}
#endif
```
